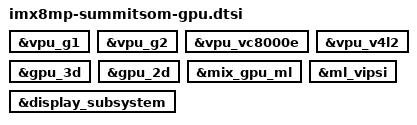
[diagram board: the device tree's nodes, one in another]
// SPDX-License-Identifier: (GPL-2.0+ OR MIT)
/*
 * Copyright 2021 Ezurio LLC
 */

&vpu_g1 {
	status = "okay";
};

&vpu_g2 {
	status = "okay";
};

&vpu_vc8000e {
	status = "okay";
};

&vpu_v4l2 {
	status = "okay";
};

&gpu_3d {
	status = "okay";
};

&gpu_2d {
	status = "okay";
};

&mix_gpu_ml {
	status = "okay";
};

&ml_vipsi {
	status = "okay";
};

&display_subsystem {
	status = "okay";
};
